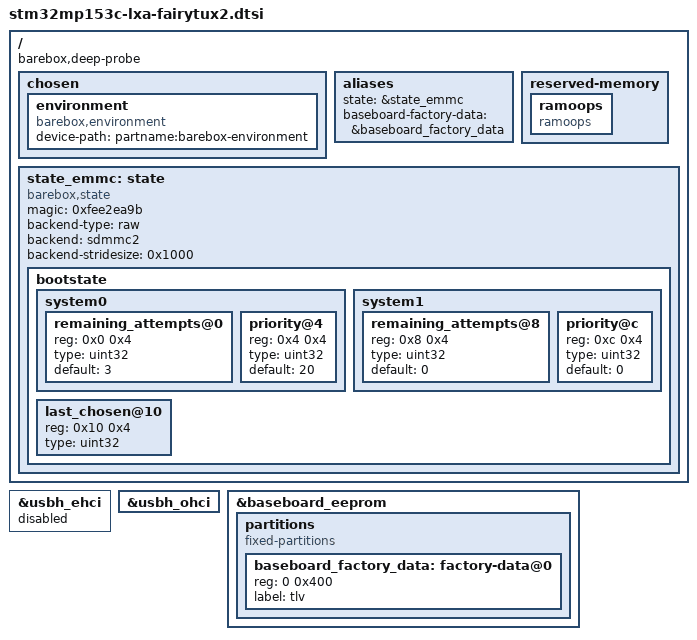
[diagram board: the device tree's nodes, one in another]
// SPDX-License-Identifier: (GPL-2.0+ OR BSD-3-Clause)
/*
 * Copyright (C) 2020 Ahmad Fatoum, Pengutronix
 * Copyright (C) 2024 Leonard Goehrs, Pengutronix
 */

#include "stm32mp151.dtsi"

/ {
	barebox,deep-probe;

	chosen {
		environment {
			compatible = "barebox,environment";
			device-path = &sdmmc2, "partname:barebox-environment";
		};
	};

	aliases {
		state = &state_emmc;
		baseboard-factory-data = &baseboard_factory_data;
	};

	reserved-memory {
		ramoops {
			compatible = "ramoops";
			/* Everything else will be fixed up at runtime */
		};
	};

	state_emmc: state {
		#address-cells = <1>;
		#size-cells = <1>;
		compatible = "barebox,state";
		magic = <0xfee2ea9b>;
		backend-type = "raw";
		backend = <&sdmmc2>;
		backend-stridesize = <0x1000>;

		bootstate {
			#address-cells = <1>;
			#size-cells = <1>;

			system0 {
				#address-cells = <1>;
				#size-cells = <1>;

				remaining_attempts@0 {
					reg = <0x0 0x4>;
					type = "uint32";
					default = <3>;
				};

				priority@4 {
					reg = <0x4 0x4>;
					type = "uint32";
					default = <20>;
				};
			};

			system1 {
				#address-cells = <1>;
				#size-cells = <1>;

				remaining_attempts@8 {
					reg = <0x8 0x4>;
					type = "uint32";
					default = <0>;
				};

				priority@c {
					reg = <0xc 0x4>;
					type = "uint32";
					default = <0>;
				};
			};

			last_chosen@10 {
				reg = <0x10 0x4>;
				type = "uint32";
			};
		};
	};
};

&usbh_ehci {
	status = "disabled";
};

&usbh_ohci {
	status = "okay";
};

&baseboard_eeprom {
	partitions {
		compatible = "fixed-partitions";
		#address-cells = <1>;
		#size-cells = <1>;

		baseboard_factory_data: factory-data@0 {
			reg = <0 0x400>;
			label = "tlv";
		};
	};
};
